# ESP32S31_RADIO register map
Vendor: Espressif; Series: ESP32-S31; File version: 3.52
Registers are 32-bit, read-write, no defined reset value unless marked. A register's access mark holds for its fields unless they carry their own. Offsets are from the block's base; [hi:lo] are bit positions; {n}, {i} and the like mark numbered series.

## WIFI_MAC_ANTENNA_INIT — Complete hal_attenna_init transaction. The misspelled vendor symbol first visits eight reverse-stride queue/vector words, then updates one common word.
Base 0x201042B0
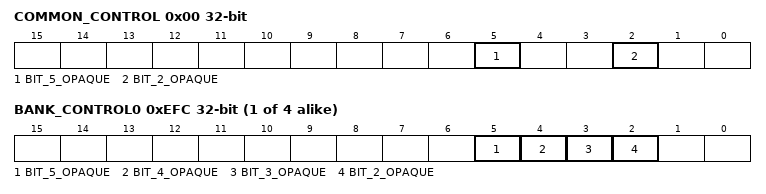
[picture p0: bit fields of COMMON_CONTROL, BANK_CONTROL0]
0x00 COMMON_CONTROL — Project-assigned name. Complete leaf clears bit 2, then sets bit 5 through a separate fresh-read RMW.
  [5] BIT_5_OPAQUE — Opaque: meaning not established. Set by the final RMW of the complete leaf.
  [2] BIT_2_OPAQUE — Opaque: meaning not established. Cleared by the penultimate RMW of the complete leaf.
{0xEFC+0x7C*i} BANK_CONTROL{i} (i=0..3) — Project-assigned name. Lower four unique words of the eight-word antenna traversal, at 0x201051ac..0x20105320. The upper four words are the canonical WIFI_MAC_TX_QUEUE_VECTOR.LENGTH_CONTROL array, whose decoded antenna fields occupy the same bits.
  [5] BIT_5_OPAQUE — Opaque: meaning not established. Set in the middle RMW of each word in the second reverse traversal.
  [4] BIT_4_OPAQUE — Opaque: meaning not established. Cleared in the third RMW of each word in the second reverse traversal.
  [3] BIT_3_OPAQUE — Opaque: meaning not established. Cleared in the first RMW of each word in the second reverse traversal.
  [2] BIT_2_OPAQUE — Opaque: meaning not established. Cleared for all eight words in the first reverse traversal.

## WIFI_MAC_TSF_STATUS — Station TSF activity status recovered from the complete no-call hal_is_sta_tsf_active leaf. The instruction body proves the address and bit geometry but not the hardware transition rules.
Base 0x2010D80C
0x00 STATUS ro — Project-assigned name. Complete hal_is_sta_tsf_active returns bit zero.
  [0] STATION_ACTIVE — Project-assigned name.
0x04 WAKEUP_SIGNAL_CLEAR — Project-assigned name. Complete libpp[pm.o]::pm_clear_wakeup_signal sets bit zero before invoking two externally supplied synchronization callbacks; hardware clear behavior remains unknown.
  [0] CLEAR — Project-assigned name.

## WIFI_MAC_STA_TBTT_TARGET — Station TBTT target word recovered from complete hal_set_sta_tbtt. The low 26-bit packing from the supplied 64-bit TSF value is exact; the hardware counter unit remains unnamed.
Base 0x2010D82C
0x00 TARGET — Project-assigned name. Complete hal_set_sta_tbtt replaces bits 25:0 with bits 35:10 of the supplied station TSF value and preserves the high six bits.
  [25:0] TSF_BITS_35_10 — Project-assigned name.

## WIFI_MAC_STA_TSF_LOAD — Shared TSF load and coherent station/SoftAP snapshot transaction.
Base 0x2010D814
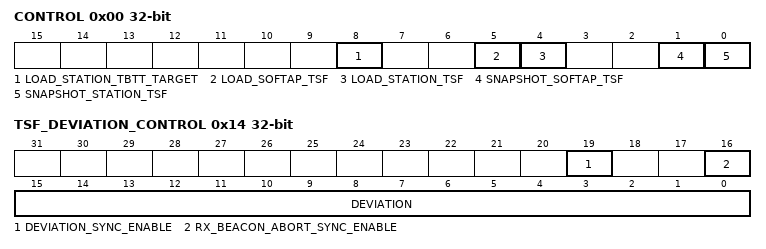
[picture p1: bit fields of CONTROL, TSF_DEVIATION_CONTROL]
0x00 CONTROL — Project-assigned name. Complete hal_set_sta_tsf asserts bit four after writing both station TSF value words; the SoftAP path of complete hal_mac_tsf_reset asserts bit five after clearing both shared TSF value words; complete libpp[hal_tsf.o]::hal_get_sta_tsf sets then clears bit zero around its snapshot reads. Complete libpp[hal_mac.o]::hal_get_tsf_time selects station with bit zero or SoftAP with bit one, reads the shared snapshot words, then clears that selector through a fresh-read RMW. The whole select/read/release transaction must be serialized across TSF domains.
  [8] LOAD_STATION_TBTT_TARGET — Project-assigned name. Complete hal_set_sta_tbtt and the index-0 TBTT start-time leaf set this bit after writing the station TBTT target.
  [5] LOAD_SOFTAP_TSF — Project-assigned name. SoftAP TSF load request asserted after the two zero-value writes by the arg0=0 path of complete hal_mac_tsf_reset.
  [4] LOAD_STATION_TSF — Project-assigned name. Station TSF load request asserted by the final fresh-read RMW in hal_set_sta_tsf.
  [1] SNAPSHOT_SOFTAP_TSF — Project-assigned name. SoftAP TSF-1 snapshot selector. Complete libpp[hal_mac.o]::hal_get_tsf_time with a nonzero argument sets this bit, reads SNAPSHOT_HIGH then SNAPSHOT_LOW, and clears this bit through a fresh-read RMW. Both readback words are shared with the station snapshot; this selector does not establish on-air beacon or probe-response timestamp insertion.
  [0] SNAPSHOT_STATION_TSF — Project-assigned name. Complete libpp[hal_tsf.o]::hal_get_sta_tsf sets this bit before either station TSF word is sampled and clears it after the optional reads.
0x04 VALUE_LOW wo — Project-assigned name. Low 32 bits written first by complete hal_set_sta_tsf.
  [31:0] VALUE — Project-assigned name.
0x08 VALUE_HIGH wo — Project-assigned name. High 32 bits written second by complete hal_set_sta_tsf.
  [31:0] VALUE — Project-assigned name.
0x0C SNAPSHOT_LOW ro — Project-assigned name. Shared coherently latched low 32 bits: conditionally read by complete libpp[hal_tsf.o]::hal_get_sta_tsf for station and read by complete libpp[hal_mac.o]::hal_get_tsf_time for the selected station/SoftAP domain.
  [31:0] VALUE — Project-assigned name.
0x10 SNAPSHOT_HIGH ro — Project-assigned name. Shared coherently latched high 32 bits: conditionally read by complete libpp[hal_tsf.o]::hal_get_sta_tsf for station and read by complete libpp[hal_mac.o]::hal_get_tsf_time for the selected station/SoftAP domain.
  [31:0] VALUE — Project-assigned name.
0x14 TSF_DEVIATION_CONTROL — Project-assigned name. Complete ROM leaves independently replace the TSF deviation value and set two synchronization controls; omitted bits remain semantically unknown.
  [19] DEVIATION_SYNC_ENABLE — Project-assigned name.
  [16] RX_BEACON_ABORT_SYNC_ENABLE — Project-assigned name.
  [15:0] DEVIATION — Project-assigned name.
